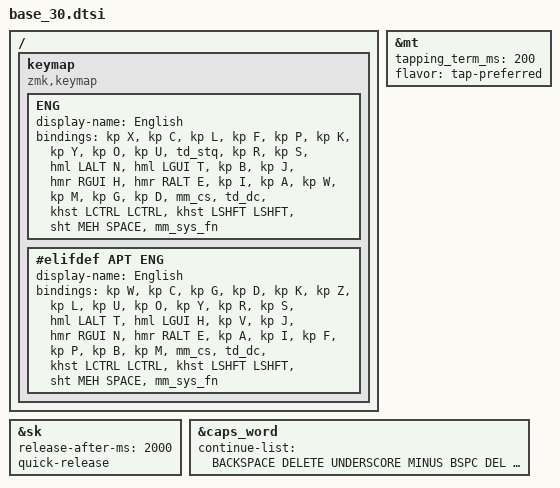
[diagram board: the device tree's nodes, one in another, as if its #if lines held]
/*
 * Copyright (c) 2020 The ZMK Contributors
 *
 * SPDX-License-Identifier: MIT
 */

#include <behaviors.dtsi>
#include <dt-bindings/zmk/bt.h>
#include <dt-bindings/zmk/keys.h>
#include <dt-bindings/zmk/outputs.h>
#include <dt-bindings/zmk/mouse.h>

// Hebrew Keymap
#include "hebrew.h"

// Extra Keys
#include "shortcut.h"

#define MEH LC(LS(LALT))
#define HYP LC(LS(LA(LGUI)))

// Behaviors Constants
#define long_tap 200
#define short_tap 150

// Combos Constants
// #define default_timeout 50

// Layers
#define ENG     0
#define HEB     1
#define SYS     2
#define FUN     3
#define ATB     4
#define BLE     5

/*
* KEY POSITIONS
*         ╭───────────────────────╮ ╭───────────────────────╮
* HIGH:   │  LH4 LH3 LH2 LH1 LH0  │ │  RH0 RH1 RH2 RH3 RH4  │
* MIDDLE: │  LM4 LM3 LM2 LM1 LM0  │ │  RM0 RM1 RM2 RM3 RM4  │
* LOW:    │      LL3 LL2 LL1      │ │      RL1 RL2 RL3      │
* THUMB:  ╰──────────╮   LT1 LT0  │ │  RT0 RT1 ╭────────────╯
*                    ╰────────────╯ ╰──────────╯ 
*/

#define KEYS_LH LH4 LH3 LH2 LH1 LH0
#define KEYS_LM LM4 LM3 LM2 LM1 LM0
#define KEYS_LL LL3 LL2 LL1
#define KEYS_RH RH4 RH3 RH2 RH1 RH0
#define KEYS_RM RM4 RM3 RM2 RM1 RM0
#define KEYS_RL RL3 RL2 RL1

#define KEYS_L KEYS_LH KEYS_LM KEYS_LL
#define KEYS_R KEYS_RH KEYS_RM KEYS_RL

#include "_behaviors.dtsi"
#include "_macros.dtsi"
#include "_combos_23332_2.dtsi"
// #include "_mouse.dtsi"

// Layers
#include "layer_heb.dtsi"
#include "layer_sys.dtsi"
#include "layer_fun.dtsi"
#include "layer_ble.dtsi"
#include "layer_atb.dtsi"

// Behavior Defaults
// Mod-Tap
&mt {
    tapping_term_ms = <200>;
    flavor = "tap-preferred";
};
// Sticky-Key
&sk {
    release-after-ms = <2000>;
    quick-release;
};

&caps_word { continue-list = <BACKSPACE DELETE UNDERSCORE MINUS BSPC DEL N1 N2 N3 N4 N5 N6 N7 N8 N9 N0>; };

/ {
    keymap {
        compatible = "zmk,keymap";
#ifdef BIRD
        ENG {
            display-name = "English";
            bindings = <
&kp X    &kp C  &kp L        &kp F              &kp P                &kp K           &kp Y        &kp O        &kp U   &td_stq
&kp R    &kp S  &hml LALT N  &hml LGUI T        &kp B                &kp J           &hmr RGUI H  &hmr RALT E  &kp I   &kp A
         &kp W  &kp M        &kp G                                                   &kp D        &mm_cs       &td_dc
                             &khst LCTRL LCTRL  &khst LSHFT LSHFT    &sht MEH SPACE  &mm_sys_fn
            >;
        };
#elifdef APT
        ENG {
            display-name = "English";
            bindings = <
&kp W   &kp C   &kp G       &kp D               &kp K               &kp Z           &kp L       &kp U       &kp O   &kp Y
&kp R   &kp S   &hml LALT T &hml LGUI H         &kp V               &kp J           &hmr RGUI N &hmr RALT E &kp A   &kp I
        &kp F   &kp P       &kp B                                                   &kp M       &mm_cs      &td_dc
                            &khst LCTRL LCTRL   &khst LSHFT LSHFT   &sht MEH SPACE  &mm_sys_fn
            >;
        };
#else
        ENG {
            display-name = "English";
            bindings = <
&kp Q    &kp W  &kp C        &kp P              &kp B                &kp J           &kp L        &kp U        &kp Y   &td_stq
&kp A    &kp R  &hml LALT S  &hml LGUI T        &kp G                &kp M           &hmr RGUI N  &hmr RALT E  &kp I   &kp O
         &kp X  &kp F        &kp D                                                   &kp H        &mm_cs       &td_dc
                             &khst LCTRL LCTRL  &khst LSHFT LSHFT    &sht MEH SPACE  &mm_sys_fn
            >;
        };
#endif
    };
};
